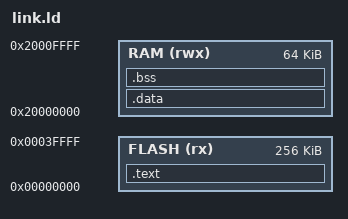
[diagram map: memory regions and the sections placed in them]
/* Runs on the micro:bit V2 simulator (flash 0x0, RAM 0x20000000) and on FVP_MPS2_Cortex-M4. */
MEMORY
{
  FLASH (rx)  : ORIGIN = 0x00000000, LENGTH = 256K
  RAM   (rwx) : ORIGIN = 0x20000000, LENGTH = 64K
}
ENTRY(Reset_Handler)
SECTIONS
{
  .text : {
    KEEP(*(.vectors))
    *(.text*)
    *(.rodata*)
    . = ALIGN(4);
    __etext = .;
  } > FLASH
  .data : AT(__etext) {
    __data_start = .;
    *(.data*)
    . = ALIGN(4);
    __data_end = .;
  } > RAM
  .bss (NOLOAD) : {
    __bss_start = .;
    *(.bss*)
    *(COMMON)
    . = ALIGN(4);
    __bss_end = .;
  } > RAM
  __stack_top = ORIGIN(RAM) + LENGTH(RAM);
}
